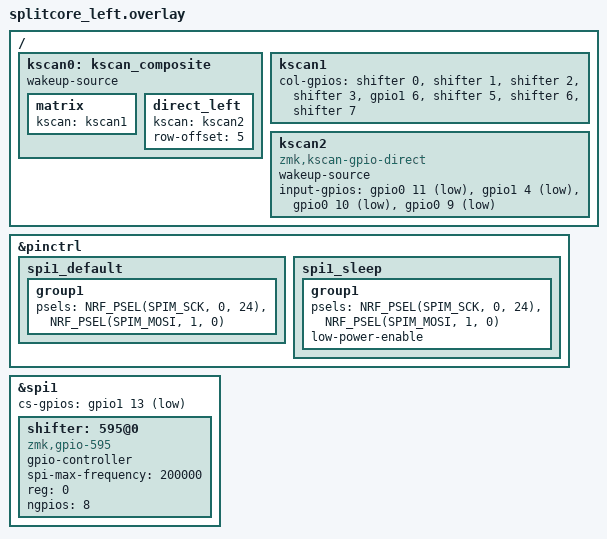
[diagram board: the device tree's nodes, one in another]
#include "splitcore.dtsi"

/ {

    kscan0: kscan_composite {
        wakeup-source;
        // matrix driver
        matrix {
            kscan = <&kscan1>;
        };
        // direct GPIO driver for dpad buttons
        direct_left {
            kscan = <&kscan2>;
            row-offset = <5>;
        };
    };

    kscan1: kscan1 {
        status = "okay";

        col-gpios
            = <&shifter 0   (GPIO_ACTIVE_HIGH)>
            , <&shifter 1   (GPIO_ACTIVE_HIGH)>
            , <&shifter 2   (GPIO_ACTIVE_HIGH)>
            , <&shifter 3   (GPIO_ACTIVE_HIGH)>
            , <&gpio1   6   (GPIO_ACTIVE_HIGH)>         // so we can wake from deep sleep
            , <&shifter 5   (GPIO_ACTIVE_HIGH)>
            , <&shifter 6   (GPIO_ACTIVE_HIGH)>
            , <&shifter 7   (GPIO_ACTIVE_HIGH)>
            ;
    };

    // dpad buttons
    kscan2: kscan2 {
        compatible = "zmk,kscan-gpio-direct";
        wakeup-source;
        status = "okay";
        input-gpios
            = <&gpio0 11    (GPIO_ACTIVE_LOW | GPIO_PULL_UP)>
            , <&gpio1 4     (GPIO_ACTIVE_LOW | GPIO_PULL_UP)>
            , <&gpio0 10    (GPIO_ACTIVE_LOW | GPIO_PULL_UP)>
            , <&gpio0 9     (GPIO_ACTIVE_LOW | GPIO_PULL_UP)>
            ;
    };
};

&pinctrl {
    // spi for the shift register
    spi1_default: spi1_default {
        group1 {
            psels = <NRF_PSEL(SPIM_SCK, 0, 24)>,
                    <NRF_PSEL(SPIM_MOSI, 1, 0)>;
        };
    };
    spi1_sleep: spi1_sleep {
        group1 {
            psels = <NRF_PSEL(SPIM_SCK, 0, 24)>,
                    <NRF_PSEL(SPIM_MOSI, 1, 0)>;
            low-power-enable;
        };
    };
};

&spi1 {
    status = "okay";
    cs-gpios = <&gpio1 13 GPIO_ACTIVE_LOW>;

    shifter: 595@0 {
        compatible = "zmk,gpio-595";
        status = "okay";
        gpio-controller;
        spi-max-frequency = <200000>;
        reg = <0>;
        #gpio-cells = <2>;
        ngpios = <8>;
    };
};
